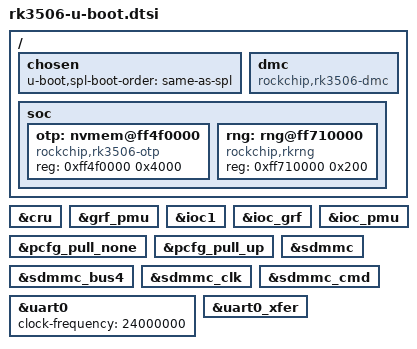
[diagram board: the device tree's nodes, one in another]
// SPDX-License-Identifier: (GPL-2.0+ OR MIT)

#include "rockchip-u-boot.dtsi"

/ {
	chosen {
		u-boot,spl-boot-order = "same-as-spl", &sdmmc;
	};

	dmc {
		compatible = "rockchip,rk3506-dmc";
		bootph-all;
	};

	soc {
		otp: nvmem@ff4f0000 {
			compatible = "rockchip,rk3506-otp";
			reg = <0xff4f0000 0x4000>;
		};

		rng: rng@ff710000 {
			compatible = "rockchip,rkrng";
			reg = <0xff710000 0x200>;
		};
	};
};

&cru {
	bootph-all;
};

&grf_pmu {
	bootph-all;
};

&ioc1 {
	bootph-all;
};

&ioc_grf {
	bootph-all;
};

&ioc_pmu {
	bootph-all;
};

&otp {
	bootph-some-ram;
};

&pcfg_pull_none {
	bootph-all;
};

&pcfg_pull_up {
	bootph-all;
};

&sdmmc {
	bootph-pre-ram;
	bootph-some-ram;
};

&sdmmc_bus4 {
	bootph-pre-ram;
	bootph-some-ram;
};

&sdmmc_clk {
	bootph-pre-ram;
	bootph-some-ram;
};

&sdmmc_cmd {
	bootph-pre-ram;
	bootph-some-ram;
};

&uart0 {
	bootph-all;
	clock-frequency = <24000000>;
};

&uart0_xfer {
	bootph-pre-sram;
	bootph-pre-ram;
};
